AUTOSAR XML (schema 4-0-3)
package /ComponentTypes
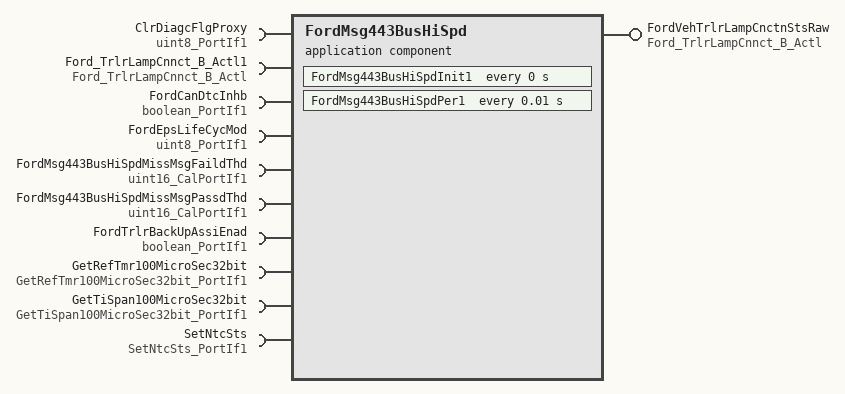
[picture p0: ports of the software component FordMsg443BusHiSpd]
  application sw component type FordMsg443BusHiSpd
    provide port FordVehTrlrLampCnctnStsRaw: nonqueued-sender-com-spec{data-element=Ford_TrlrLampCnnct_B_Actl, init-value=0}, provided-interface=Ford_TrlrLampCnnct_B_Actl
    10 x require port:
      ClrDiagcFlgProxy: nonqueued-receiver-com-spec{data-element=Val, filter=data-filter-type=ALWAYS, init-value=0}, required-interface=uint8_PortIf1
      Ford_TrlrLampCnnct_B_Actl1: nonqueued-receiver-com-spec{data-element=Ford_TrlrLampCnnct_B_Actl, filter=data-filter-type=ALWAYS, init-value=0}, required-interface=Ford_TrlrLampCnnct_B_Actl
      FordCanDtcInhb: nonqueued-receiver-com-spec{data-element=Logl, filter=data-filter-type=ALWAYS, init-value=1}, required-interface=boolean_PortIf1
      FordEpsLifeCycMod: nonqueued-receiver-com-spec{data-element=Val, filter=data-filter-type=ALWAYS, init-value=0}, required-interface=uint8_PortIf1
      FordMsg443BusHiSpdMissMsgFaildThd: parameter-require-com-spec{init-value=5000, parameter=Val}, required-interface=uint16_CalPortIf1
      FordMsg443BusHiSpdMissMsgPassdThd: parameter-require-com-spec{init-value=0, parameter=Val}, required-interface=uint16_CalPortIf1
      FordTrlrBackUpAssiEnad: nonqueued-receiver-com-spec{data-element=Logl, filter=data-filter-type=ALWAYS, init-value=0}, required-interface=boolean_PortIf1
      GetRefTmr100MicroSec32bit: client-com-spec=Oper, required-interface=GetRefTmr100MicroSec32bit_PortIf1
      GetTiSpan100MicroSec32bit: client-com-spec=Oper, required-interface=GetTiSpan100MicroSec32bit_PortIf1
      SetNtcSts: client-com-spec=Oper, required-interface=SetNtcSts_PortIf1
    behavior FordMsg443BusHiSpd_InternalBehavior
      ar-typed-per-instance-memorys:
        5 x data, all with sw-calibration-access=READ-ONLY:
          ClrDiagcFlgProxyPrev: type=uint8
          FordVehMsg443Miss: type=boolean
          FordVehTrlrLampCnctnStsRawPrev: type=Ford_TrlrLampCnnct_B_Actl
          MissMsgFaildRefTi: type=uint32
          MissMsgPassdRefTi: type=uint32
      timing event FordMsg443BusHiSpd_InitEvent: start-on-event=FordMsg443BusHiSpdInit1, period=0
      timing event TMT_FordMsg443BusHiSpdPer1: start-on-event=FordMsg443BusHiSpdPer1, period=0.01
      port-api-options:
        enable-take-address=false, indirect-api=false, port=ClrDiagcFlgProxy
        enable-take-address=false, indirect-api=false, port=Ford_TrlrLampCnnct_B_Actl1
        enable-take-address=false, indirect-api=false, port=FordCanDtcInhb
        enable-take-address=false, indirect-api=false, port=FordEpsLifeCycMod
        enable-take-address=false, indirect-api=false, port=FordMsg443BusHiSpdMissMsgFaildThd
        enable-take-address=false, indirect-api=false, port=FordMsg443BusHiSpdMissMsgPassdThd
        enable-take-address=false, indirect-api=false, port=FordTrlrBackUpAssiEnad
        enable-take-address=false, indirect-api=false, port=FordVehTrlrLampCnctnStsRaw
        enable-take-address=false, indirect-api=false, port=GetRefTmr100MicroSec32bit
        enable-take-address=false, indirect-api=false, port=GetTiSpan100MicroSec32bit
        enable-take-address=false, indirect-api=false, port=SetNtcSts
      runnable FordMsg443BusHiSpdInit1
        sync call SC_GetRefTmr100MicroSec32bit_Oper: operation=GetRefTmr100MicroSec32bit.Oper, timeout=0
      runnable FordMsg443BusHiSpdPer1
        data-receive-point-by-arguments:
          5 x access:
            REC_ClrDiagcFlgProxy_Val: accessed-variable=ClrDiagcFlgProxy.Val
            REC_Ford_TrlrLampCnnct_B_Actl_Ford_TrlrLampCnnct_B_Actl: accessed-variable=Ford_TrlrLampCnnct_B_Actl1.Ford_TrlrLampCnnct_B_Actl
            REC_FordCanDtcInhb_Logl: accessed-variable=FordCanDtcInhb.Logl
            REC_FordEpsLifeCycMod_Val: accessed-variable=FordEpsLifeCycMod.Val
            REC_FordTrlrBackUpAssiEnad_Logl: accessed-variable=FordTrlrBackUpAssiEnad.Logl
        data-send-points:
          access SEND_FordVehTrlrLampCnctnStsRaw_Ford_TrlrLampCnnct_B_Actl: accessed-variable=FordVehTrlrLampCnctnStsRaw.Ford_TrlrLampCnnct_B_Actl
        sync call SC_GetRefTmr100MicroSec32bit_Oper: operation=GetRefTmr100MicroSec32bit.Oper, timeout=0
        sync call SC_GetTiSpan100MicroSec32bit_Oper: operation=GetTiSpan100MicroSec32bit.Oper, timeout=0
        sync call SC_SetNtcSts_Oper: operation=SetNtcSts.Oper, timeout=0
  swc implementation FordMsg443BusHiSpd_Implementation: behavior=FordMsg443BusHiSpd_InternalBehavior
    code-descriptors:
      code Default: artifact-descriptors=autosar-engineering-object={short-label=Default, category=SWSRC}
